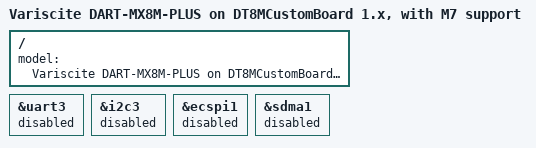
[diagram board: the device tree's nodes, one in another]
// SPDX-License-Identifier: (GPL-2.0+ OR MIT)
/*
 * Copyright 2019 NXP
 * Copyright 2020-2021 Variscite Ltd.
 */

#include "imx8mp-var-dart-dt8mcustomboard-legacy.dts"
#include "imx8mp-var-common-m7.dtsi"

/ {
	model = "Variscite DART-MX8M-PLUS on DT8MCustomBoard 1.x, with M7 support";
};

/*
 * ATTENTION: M7 may use IPs like below
 * ECSPI1, I2C3, UART3, PWM3, SDMA1
 */

&uart3 {
	status = "disabled";
};

&i2c3 {
	status = "disabled";
};

&ecspi1 {
	status = "disabled";
};

&sdma1 {
	status = "disabled";
};
